# PIC32MM0016GPL028 device description
Architecture: MIPS; Family: PIC32MM1324; Series: PIC32MM
Registers are 32-bit, read-write, no defined reset value unless marked. A register's access mark holds for its fields unless they carry their own. Offsets are from the block's base; [hi:lo] are bit positions; {n}, {i} and the like mark numbered series; 'fields as' and 'values as' point back to an identical list.

## CMP
Instances: CMP 0x1f800900 in periph0
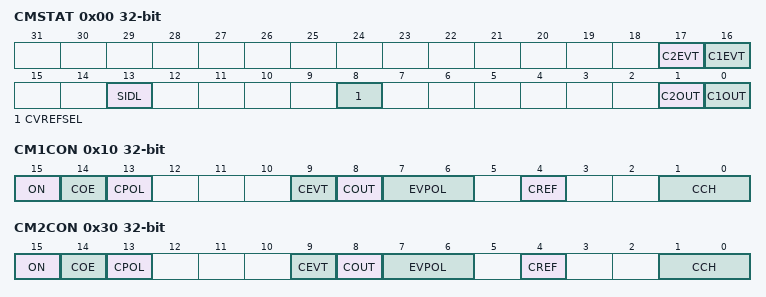
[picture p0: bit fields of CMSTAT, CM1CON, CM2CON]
0x00 CMSTAT
  [17] C2EVT
  [16] C1EVT
  [13] SIDL — Stop in Idle Control bit
    1=All Comparator modules are disabled in Idle mode; 0=All Comparator modules continue to operate in the Idle mode
  [8] CVREFSEL — Comparator Reference Voltage Select (CVREFSEL)
    1=External voltage reference from the CVREF+ pin is selected; 0=Internal band gap voltage reference is selected
  [1] C2OUT — Comparator 2 Output bit
    1=Output of Comparator 2 is a 1; 0=Output of Comparator 2 is a 0
  [0] C1OUT — Comparator 1 Output bit
    1=Output of Comparator 1 is a 1; 0=Output of Comparator 1 is a 0
0x10 CM1CON
  [15] ON — Comparator ON bit
    1=Module is enabled. Setting this bit does not affect the other bits in this register; 0=Module is disabled and does not consume current. Clearing this bit does not affect the other bits in this register
  [14] COE — Comparator Output Enable bit
    1=Comparator output is driven on the output CxOUT pin; 0=Comparator output is not driven on the output CxOUT pin
  [13] CPOL — Comparator Output Inversion bit
    1=Output is inverted; 0=Output is not inverted
  [9] CEVT
  [8] COUT — Comparator Output bit
    1=VIN+ is greater than VIN- (if CPOL = 0)/VIN+ is smaller than VIN- (if CPOL = 1); 0=VIN+ is greater than VIN- (if CPOL = 1)/VIN+ is smaller than VIN- (if CPOL = 0)
  [7:6] EVPOL — Interrupt Event Polarity Select bits
    3=Comparator event is generated on any change of the comparator output; 2=Comparator event is generated on a high-to-low transition (if CPOL = 0) or low-to-high transition (if CPOL = 1) of the comparator output; 1=Comparator event is generated on a high-to-low transition (if CPOL = 1) or low-to-high transition (if CPOL = 0) of the comparator output; 0=Comparator event generation is disabled
  [4] CREF — Comparator Positive Input Configuration
    1=Comparator Non-inverting input connects to the reference defined by the CVREFSEL bit; 0=Comparator non-inverting input is connected to the CxINA pin
  [1:0] CCH — Comparator Negative Input Configuration
    3=Comparator inverting input is connected to the band gap reference voltage; 2=Comparator inverting input is connected to the CxIND pin; 1=Comparator inverting input is connected to the CxINC pin; 0=Comparator inverting input is connected to the CxINB pin
0x30 CM2CON
  fields as CM1CON

## CRC
Instances: CRC 0x1f800a00 in periph0
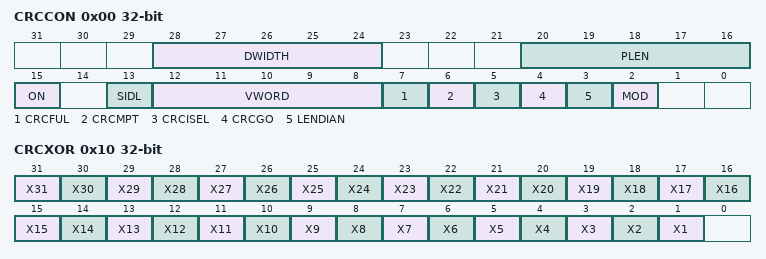
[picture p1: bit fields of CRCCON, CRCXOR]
0x00 CRCCON
  [28:24] DWIDTH, [20:16] PLEN, [15] ON, [13] SIDL, [12:8] VWORD, [7] CRCFUL, [6] CRCMPT, [5] CRCISEL, [4] CRCGO, [3] LENDIAN, [2] MOD
0x10 CRCXOR
  [n] X{n} (n=1..31)
0x20 CRCDAT wo
0x30 CRCWDAT

## HLVD
Instances: HLVD 0x1f802310 in periph0
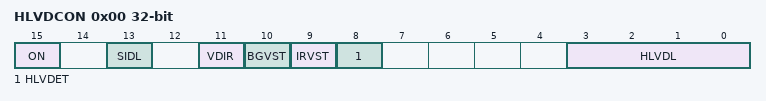
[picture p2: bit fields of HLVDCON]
0x00 HLVDCON — High/Low-Voltage Detect Control Register
  [15] ON — HLVD Module Enable bit
    1=HLVD module is enabled; 0=HLVD module is disabled
  [13] SIDL
  [11] VDIR — Voltage Change Direction Select bit
    1=Event occurs when voltage equals or exceeds the trip point (HLVDL); 0=Event occurs when voltage equals or falls below the trip point (HLVDL)
  [10] BGVST — Band Gap Reference Voltages Stable Status bit
    1=Indicates internal band gap voltage references is stable; 0=Indicates internal band gap voltage reference is not stable
  [9] IRVST — Internal Reference Voltage Stable Status bit
    1=Indicates internal reference voltage references is stable; 0=Indicates internal reference voltage reference is not stable
  [8] HLVDET — High/Low-Voltage Detection Event Status bit
    1=Indicates HLVD Event interrupt is active; 0=Indicates HLVD Event interrupt is not active
  [3:0] HLVDL — High/Low-Voltage Detection Limit Select bits
    15=External LVDIN pin; 14=VDD trip point is between 2.00V and 2.22V; 13=VDD trip point is between 2.08V and 2.33V; 12=VDD trip point is between 2.15V and 2.44V; 11=VDD trip point is between 2.25V and 2.55V; 10=VDD trip point is between 2.35V and 2.69V; 9=VDD trip point is between 2.45V and 2.80V; 8=VDD trip point is between 2.65V and 2.98V; 7=VDD trip point is between 2.75V and 3.09V; 6=VDD trip point is between 2.95V and 3.30V; 5=VDD trip point is between 3.25V and 3.63V; {v}=Reserved; do not use (v=0..4)

## Notices in the file
Copyright (c) 2019 Microchip Technology Inc.
SPDX-License-Identifier: Apache-2.0
Licensed under the Apache License, Version 2.0 (the "License");
you may not use this file except in compliance with the License.
You may obtain a copy of the License at
http://www.apache.org/licenses/LICENSE-2.0
Unless required by applicable law or agreed to in writing, software
distributed under the License is distributed on an "AS IS" BASIS,
WITHOUT WARRANTIES OR CONDITIONS OF ANY KIND, either express or implied.
See the License for the specific language governing permissions and
limitations under the License.
